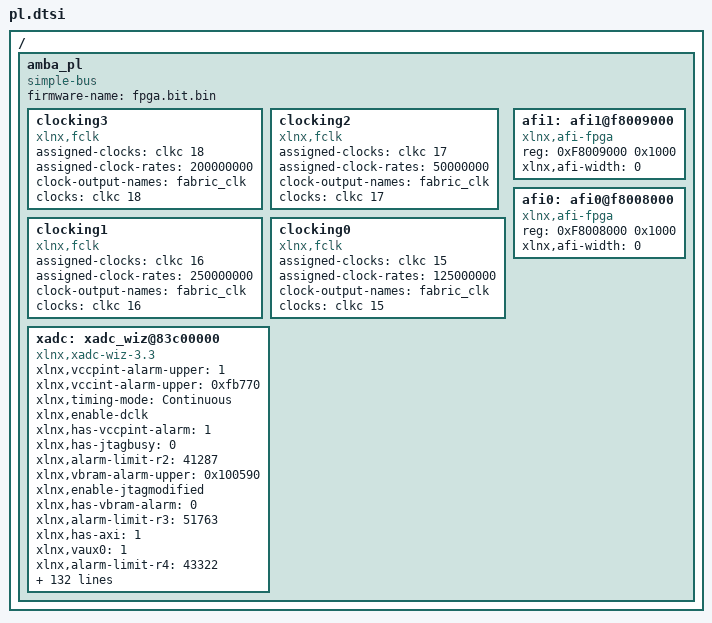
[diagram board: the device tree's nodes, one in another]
/ {
	amba_pl: amba_pl {
		ranges;
		compatible = "simple-bus";
		//#address-cells = <1>;
		//#size-cells = <1>;
		firmware-name = "fpga.bit.bin";
		clocking3: clocking3 {
			compatible = "xlnx,fclk";
			assigned-clocks = <&clkc 18>;
			assigned-clock-rates = <200000000>;
			#clock-cells = <0>;
			clock-output-names = "fabric_clk";
			clocks = <&clkc 18>;
		};
		clocking2: clocking2 {
			compatible = "xlnx,fclk";
			assigned-clocks = <&clkc 17>;
			assigned-clock-rates = <50000000>;
			#clock-cells = <0>;
			clock-output-names = "fabric_clk";
			clocks = <&clkc 17>;
		};
		clocking1: clocking1 {
			compatible = "xlnx,fclk";
			assigned-clocks = <&clkc 16>;
			assigned-clock-rates = <250000000>;
			#clock-cells = <0>;
			clock-output-names = "fabric_clk";
			clocks = <&clkc 16>;
		};
		clocking0: clocking0 {
			compatible = "xlnx,fclk";
			assigned-clocks = <&clkc 15>;
			assigned-clock-rates = <125000000>;
			#clock-cells = <0>;
			clock-output-names = "fabric_clk";
			clocks = <&clkc 15>;
		};
		afi1: afi1@f8009000 {
			status = "okay";
			compatible = "xlnx,afi-fpga";
			//#address-cells = <1>;
			reg = <0xF8009000 0x1000>;
			//#size-cells = <0>;
			xlnx,afi-width = <0>;
		};
		afi0: afi0@f8008000 {
			status = "okay";
			compatible = "xlnx,afi-fpga";
			//#address-cells = <1>;
			reg = <0xF8008000 0x1000>;
			//#size-cells = <0>;
			xlnx,afi-width = <0>;
		};
		xadc: xadc_wiz@83c00000 {
			xlnx,vccpint-alarm-upper = <1>;
			xlnx,vccint-alarm-upper = <0xfb770>;
			xlnx,timing-mode = "Continuous";
			xlnx,enable-dclk;
			xlnx,has-vccpint-alarm = <1>;
			xlnx,has-jtagbusy = <0>;
			xlnx,alarm-limit-r2 = <41287>;
			xlnx,vbram-alarm-upper = <0x100590>;
			xlnx,enable-jtagmodified;
			xlnx,has-vbram-alarm = <0>;
			xlnx,alarm-limit-r3 = <51763>;
			xlnx,has-axi = <1>;
			xlnx,vaux0 = <1>;
			xlnx,alarm-limit-r4 = <43322>;
			xlnx,has-busy = <1>;
			xlnx,ot-alarm;
			xlnx,enable-channel;
			xlnx,vaux1 = <1>;
			xlnx,has-vccaux-alarm = <1>;
			xlnx,alarm-limit-r5 = <21190>;
			xlnx,dclk-frequency = <100>;
			xlnx,rable = <0>;
			xlnx,vaux2 = <0>;
			xlnx,alarm-limit-r6 = <38229>;
			xlnx,vaux3 = <0>;
			xlnx,ip-name = "xadc_wiz";
			xlnx,alarm-limit-r7 = <44622>;
			xlnx,configuration-r0 = <0>;
			xlnx,has-drp = <0>;
			xlnx,vaux4 = <0>;
			xlnx,sim-file-rel-path = "./";
			reg = <0x83c00000 0x10000>;
			xlnx,alarm-limit-r8 = <22937>;
			xlnx,configuration-r1 = <33024>;
			xlnx,external-mux-channel = "VP_VN";
			xlnx,vccint-alarm;
			xlnx,temperature-alarm-trigger = <85>;
			xlnx,vaux5 = <0>;
			xlnx,has-jtaglocked = <0>;
			xlnx,alarm-limit-r9 = <20753>;
			xlnx,configuration-r2 = <1024>;
			xlnx,vaux6 = <0>;
			xlnx,vaux7 = <0>;
			xlnx,user-temp-alarm;
			xlnx,vaux8 = <1>;
			xlnx,vaux9 = <1>;
			xlnx,vaux10 = <0>;
			xlnx,has-vn = <1>;
			xlnx,has-vccpaux-alarm = <1>;
			xlnx,acquisition-time = <4>;
			xlnx,vaux11 = <0>;
			xlnx,has-temp-bus = <0>;
			xlnx,xadc-starup-selection = "independent_adc";
			xlnx,enable-busy;
			xlnx,data-width = <32>;
			xlnx,vaux12 = <0>;
			xlnx,sim-file-sel = "Default";
			xlnx,has-vp = <1>;
			xlnx,ip-type = <0x0>;
			interrupt-names = "ip2intc_irpt";
			xlnx,temperature-alarm-ot-reset = <70>;
			xlnx,vaux13 = <0>;
			xlnx,enable-convst;
			xlnx,vaux14 = <0>;
			xlnx,channel-enable-vp-vn;
			xlnx,vccpaux-alarm-lower = <0x1a17b0>;
			xlnx,vccaux-alarm-lower = <0x1ab3f0>;
			xlnx,vaux15 = <0>;
			compatible = "xlnx,xadc-wiz-3.3" , "xlnx,axi-xadc-1.00.a";
			xlnx,has-external-mux = <0>;
			xlnx,vccaux-alarm;
			xlnx,sampling-rate = <0x7fffffff>;
			xlnx,has-reset = <0>;
			xlnx,adc-conversion-rate = <1000>;
			xlnx,vccddro-alarm-lower = <0x124f80>;
			xlnx,enable-calibration-averaging;
			xlnx,has-user-temp-alarm = <1>;
			interrupt-parent = <&intc>;
			xlnx,has-ot-alarm = <1>;
			xlnx,has-convst = <0>;
			xlnx,channel-enable-vauxp1-vauxn1;
			xlnx,single-channel-selection = "TEMPERATURE";
			xlnx,startup-channel-selection = "single_channel";
			xlnx,interface-selection = "Enable_AXI";
			xlnx,vccpaux-alarm-upper = <0x1b7740>;
			xlnx,vccaux-alarm-upper = <0x1cd6d0>;
			xlnx,channel-enable-vauxp0-vauxn0;
			status = "okay";
			xlnx,sensor-offset-and-gain-calibration;
			xlnx,vccddro-alarm-upper = <0x1312d0>;
			xlnx,name = "xadc";
			xlnx,external-mux = "none";
			interrupts = < 0 29 4 >;
			xlnx,enable-vccddro-alarm;
			xlnx,enable-eoc;
			xlnx,enable-jtaglocked;
			xlnx,sim-file-name = "design";
			xlnx,enable-vccpint-alarm;
			xlnx,channel-enable-vauxp9-vauxn9;
			xlnx,temperature-alarm-reset = <60>;
			xlnx,addr-width = <32>;
			clocks = <&clkc 18>;
			xlnx,alarm-limit-r10 = <21845>;
			xlnx,alarm-limit-r11 = <20753>;
			xlnx,alarm-limit-r12 = <39321>;
			xlnx,edk-iptype = "PERIPHERAL";
			xlnx,alarm-limit-r13 = <37355>;
			xlnx,sequencer-mode;
			xlnx,enable-jtagbusy;
			xlnx,alarm-limit-r14 = <27306>;
			xlnx,channel-enable-vauxp8-vauxn8;
			xlnx,include-intr = <1>;
			xlnx,alarm-limit-r15 = <26214>;
			xlnx,fifo-depth = <7>;
			clock-names = "s_axi_aclk";
			xlnx,enable-vccpaux-alarm;
			xlnx,has-eoc = <1>;
			xlnx,temperature-alarm-ot-trigger = <125>;
			xlnx,has-channel = <1>;
			xlnx,enable-eos;
			xlnx,vccpint-alarm-lower = <0xe7ef0>;
			xlnx,vccint-alarm-lower = <0xecd10>;
			xlnx,has-dclk = <1>;
			xlnx,vbram-alarm-lower = <0xe7ef0>;
			xlnx,num-wave = <1>;
			xlnx,sequence-r0 = <2048>;
			xlnx,has-jtagmodified = <0>;
			xlnx,sequence-r1 = <771>;
			xlnx,enable-drp;
			xlnx,sequence-r2 = <0>;
			xlnx,has-vccint-alarm = <1>;
			xlnx,channel-averaging = "None";
			xlnx,sequence-r3 = <0>;
			xlnx,has-axi4stream = <0>;
			xlnx,sequence-r4 = <0>;
			xlnx,sequence-r5 = <0>;
			xlnx,adc-offset-and-gain-calibration;
			xlnx,waveform-type = "CONSTANT";
			xlnx,sequence-r6 = <0>;
			xlnx,vccddro-volt = "1_2";
			xlnx,sequence-r7 = <0>;
			xlnx,has-vccddro-alarm = <1>;
			xlnx,has-eos = <1>;
			xlnx,alarm-limit-r0 = <46573>;
			xlnx,has-convstclk = <0>;
			xlnx,stimulus-freq = <1>;
			xlnx,single-channel-enable-calibration;
			xlnx,alarm-limit-r1 = <22500>;
			xlnx,component-name = "system_xadc_0";
			xlnx,external-muxaddr-enable = <0>;
		};
	};
};
